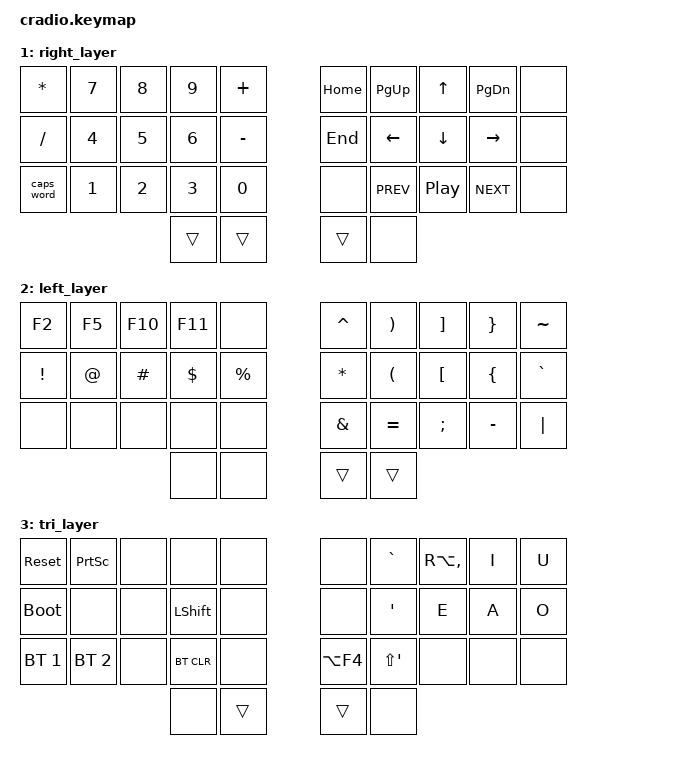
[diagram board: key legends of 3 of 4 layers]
// Copyright (c) 2022 The ZMK Contributors
// SPDX-License-Identifier: MIT

#include <behaviors.dtsi>
#include <dt-bindings/zmk/keys.h>
#include <dt-bindings/zmk/bt.h>
#include "../nodefree-config/helper.h"

// Home row mods macro
#define HRML(k1,k2,k3) &ht LALT k1  &ht LCTRL k2  &ht LGUI k3
#define HRMR(k1,k2,k3) &ht RGUI k1  &ht RCTRL k2  &ht LALT k3

// Combo macro
#define COMBO(NAME, BINDINGS, KEYPOS) \
  combo_##NAME { \
    timeout-ms = <50>; \
    bindings = <BINDINGS>; \
    key-positions = <KEYPOS>; \
  };

/ {
    behaviors {
        ht: hold_tap {
            label = "hold_tap";
            compatible = "zmk,behavior-hold-tap";
            #binding-cells = <2>;
            flavor = "tap-preferred";
            tapping-term-ms = <300>;
            quick-tap-ms = <100>;
            global-quick-tap;
            bindings = <&kp>, <&kp>;
        };
    };

    macros {
        macro_sqt: macro_sqt {
            label = "macro_sqt";
            compatible = "zmk,behavior-macro";
            #binding-cells = <0>;
            bindings
                = <&macro_tap &kp SQT &kp SPACE>
                ;
        };
    };

    combos {
                compatible = "zmk,combos";

                COMBO(ESC, &kp ESC, 2 3)
                COMBO(DEL, &kp DEL, 8 9)
                COMBO(TAB, &kp TAB, 1 2)
                
        };

    conditional_layers {
        compatible = "zmk,conditional-layers";
        tri_layer {
            if-layers = <1 2>;
            then-layer = <3>;
        };
    };

    keymap {
        compatible = "zmk,keymap";
        default_layer {
            bindings = <
            &kp Q  &kp W    &kp F  &kp P  &kp G      &kp J                  &kp L            &kp U       &kp Y    &macro_sqt
            &kp A  HRML(R,  S,     T)     &kp D      &kp H                  HRMR(N,          E,          I)       &kp O
            &kp Z  &kp X    &kp C  &kp V  &kp B      &kp K                  &kp M            &kp COMMA   &kp DOT  &kp FSLH
                                          &lt 2 DEL  &ht LSHFT ENTER        &ht LSHFT SPACE  &lt 1 BSPC
            >;
        };

        right_layer {
            bindings = <
            &kp STAR    &kp N7  &kp N8  &kp N9  &kp PLUS       &kp HOME  &kp PG_UP   &kp UP    &kp PG_DN   &none
            &kp SLASH   &kp N4  &kp N5  &kp N6  &kp MINUS      &kp END   &kp LEFT    &kp DOWN  &kp RIGHT   &none
            &caps_word  &kp N1  &kp N2  &kp N3  &kp N0         &none     &kp C_PREV  &kp C_PP  &kp C_NEXT  &none
                                        &trans  &trans         &trans    &none
            >;
        };

        left_layer {
            bindings = <
            &kp F2     &kp F5  &kp F10   &kp F11   &none         &kp CARET  &kp RPAR   &kp RBKT  &kp RBRC   &kp TILDE
            &kp EXCL   &kp AT  &kp HASH  &kp DLLR  &kp PRCNT     &kp STAR   &kp LPAR   &kp LBKT  &kp LBRC   &kp GRAVE
            &none      &none   &none     &none     &none         &kp AMPS   &kp EQUAL  &kp SEMI  &kp MINUS  &kp PIPE 
                                         &none     &none         &trans     &trans
            >;
        };

        tri_layer {
            bindings = <
            &sys_reset    &kp PSCRN         &none  &none       &none             &none       &kp GRAVE    &kp RA(COMMA)  &kp I  &kp U
            &bootloader   &none             &none  &kp LSHFT   &none             &none       &kp SQT      &kp E          &kp A  &kp O
            &bt BT_SEL 1  &bt BT_SEL 2      &none  &bt BT_CLR  &none             &kp LA(F4)  &kp LS(SQT)  &none          &none  &none
                                            &none       &trans            &trans      &none
            >;
        };
    };
};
